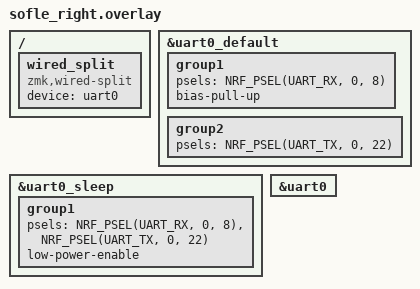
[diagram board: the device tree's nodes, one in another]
/*
 * Wired split over TRRS, full duplex (cable is straight-through):
 *   TRRS data ring  = D0 (P0.08), stock Sofle wiring
 *   TRRS spare ring = D4 (P0.22), jumper wire added on both halves
 * right half: TX on D4, RX on D0 (mirrored on the other half).
 */

&uart0_default {
    group1 {
        psels = <NRF_PSEL(UART_RX, 0, 8)>;
        bias-pull-up;
    };
    group2 {
        psels = <NRF_PSEL(UART_TX, 0, 22)>;  // replaces the board default D1, which drives the LEDs
    };
};

&uart0_sleep {
    group1 {
        psels = <NRF_PSEL(UART_RX, 0, 8)>,
                <NRF_PSEL(UART_TX, 0, 22)>;
        low-power-enable;
    };
};

&uart0 {
    status = "okay";
};

/ {
    wired_split {
        compatible = "zmk,wired-split";
        device = <&uart0>;
    };
};
